# STM32G563 register map
File version: 2.0.0
CPU: CM33 r0p4, little endian, MPU, FPU, 4 interrupt priority bits
Registers are 32-bit, read-write, reset 0x0 unless marked. A register's access mark holds for its fields unless they carry their own. Offsets are from the block's base; [hi:lo] are bit positions; {n}, {i} and the like mark numbered series.

## CCB — CCB register block
Base 0x4600DC00
Same registers: CCB_S 0x5600DC00
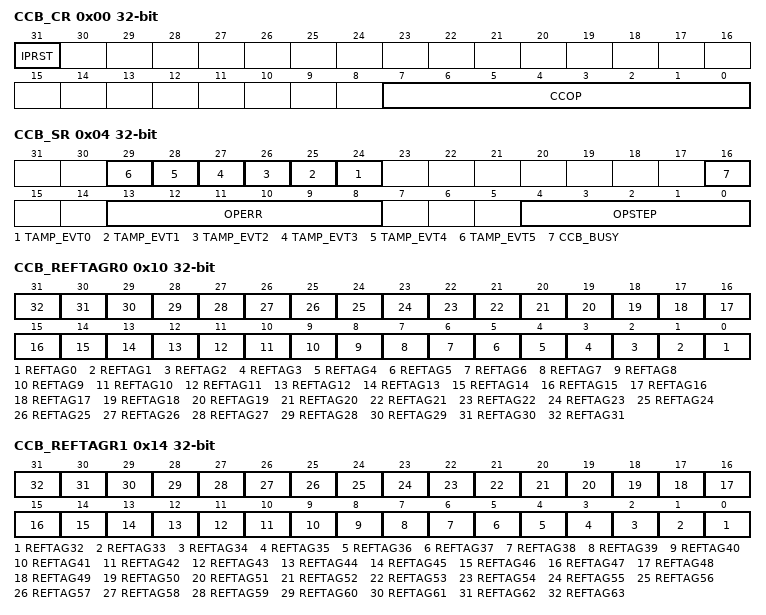
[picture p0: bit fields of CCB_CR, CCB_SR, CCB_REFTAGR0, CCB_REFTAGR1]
0x00 CCB_CR — CCB control register
  [31] IPRST — CCB reset
  [7:0] CCOP — Coupling and chaining operation
    68=Modular exponentiation blob creation with priv key from the CPU; 69=Modular exponentiation blob use; 128=ECC scalar multiplication blob creation with priv key from the CPU; 130=ECC scalar multiplication blob creation with priv key from the RNG; 129=ECC scalar multiplication blob use, or ECDSA signature blob use for public key computation; 192=ECDSA signature blob creation with priv key from the CPU; 194=ECDSA signature blob creation with priv key from the RNG; 195=ECDSA signature blob use for ECDSA signature
0x04 CCB_SR ro — CCB status register
  [n+24] TAMP_EVT{n} (n=0..5) — Tamper i flag
    0=No event; 1=Tamper event i has been raised. Global tamper event is raised. See Section43.3for details on the events.
  [16] CCB_BUSY
    0=CCB idle; 1=CCB busy or PKA RAM is being cleared following a peripheral reset
  [13:8] OPERR — Operation error
    0=No error detected during protected PKA operation (if applicable); 1=CCB RCC reset has been detected when OPSTEP > 0x0; 2=SAES RCC reset has been detected when OPSTEP > 0x0; 3=PKA RCC reset has been detected when OPSTEP > 0x0; 4=RNG RCC reset has been detected when OPSTEP > 0x0; 5=The RCC has gated the CCB clock when OPSTEP > 0x0; 6=The RCC has gated the SAES clock when OPSTEP > 0x0; 7=The RCC has gated the PKA clock when OPSTEP > 0x0; 8=The RCC has gated the RNG clock when OPSTEP > 0x0; 9=Random in SAES_IV1 is trivial (all 0s or all 1s) when OPSTEP = 0x2; 10=Random in SAES_IV2 is trivial (all 0s or all 1s) when OPSTEP = 0x2; 11=Random in SAES_IV3 is trivial (all 0s or all 1s) when OPSTEP = 0x2; 12=When OPSTEP = 0x17 SAES GCM TAG comparison with CCB_REFTAG failed, or a register different from SAES_DOUT was read in the SAES; 13=KEYSIZE different to 256 bits in SAES_CR when the SAES is enabled, and OPSTEP > 0x0; 14=CHMOD different to GCM in SAES_CR when 0x1 less than OPSTEP less than 0x18, or the SAES is not enabled, or KEYVALID is cleared when GCMPH > 0x0; 15=KMOD different from wrapped key mode in SAES_CR when the SAES is enabled, and; 16=KEYSEL different to 0x1 or 0x4 in SAES_CR when the SAES is enabled, KEYVALID is set, and OPSTEP=0x1; 17=GCMPH not correct (not incremented) in SAES_CR when OPSTEP > 0x1; 18=MODE in SAES_CR does not match the expected value (selected by CCOP in CCB_CR) when OPSTEP > 0x1; 19=BUSY = 1 in SAES_SR when OPSTEP= 0x18 or 0x19. SAES must not be used when PKA is computing a protected operation.; 20=EN = 0 in PKA_CR when OPSTEP > 0x2 (except 0x12). In other words, PKA must be enabled in any OPSTEP except 0x1, 0x2, or 0x12.; 21=INITOK = 0 in PKA_SR when OPSTEP > 0x2 (except 0x12); 22=Authorized by local firewall, but unexpected AHB error detected when OPSTEP > 0x0. 0x17: LMF = 1 in PKA_SR (only ECDSA verification available) when OPSTEP > 0x0.; 24=CCB_REFTAGRx registers are equal to 0 when OPSTEP > 0x12; 26=Security or/and privilege protection inconsistent (see Section5: Global TrustZoneless thansup> less than/sup> controller (GTZC)) for the peripherals SAES, PKA, RNG, and CCB when OPSTEP > 0x0. This error is also triggered when the protections change while OPSTEP > 0x0; 27=MODE in PKA_CR does not match the expected value (selected by CCOP in CCB_CR) when OPSTEP > 0x0; 28=OPSTEP end-step event not found at OPSTEP= 0x0 (SAES KEYVALID is set). Use CCB IPRST before starting a coupling and chaining operation.; 29=OPSTEP end-step event not found at OPSTEP = 0x1; 30=OPSTEP end-step event not found at OPSTEP = 0x2; 31=OPSTEP end-step event not found at OPSTEP = 0x3; 32=OPSTEP end-step event not found at OPSTEP = 0xA; 33=OPSTEP end-step event not found at OPSTEP = 0x12; 34=OPSTEP end-step event not found at OPSTEP = 0x13; 35=OPSTEP end-step event not found at OPSTEP = 0x17
  [4:0] OPSTEP — Operation step
0x10 CCB_REFTAGR0 — CCB reference tag register
  [n] REFTAG{n} (n=0..31) — Reference tag bits {n}
0x14 CCB_REFTAGR1 — CCB reference tag register
  [n-32] REFTAG{n} (n=32..63) — Reference tag bits {n}
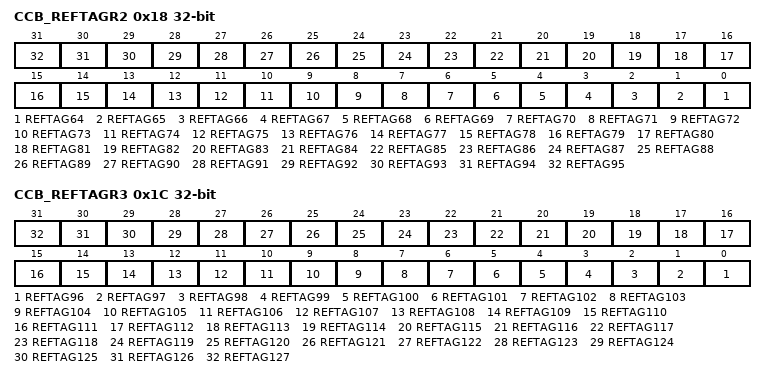
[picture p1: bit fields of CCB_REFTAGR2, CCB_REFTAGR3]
0x18 CCB_REFTAGR2 — CCB reference tag register
  [n-64] REFTAG{n} (n=64..95) — Reference tag bits {n}
0x1C CCB_REFTAGR3 — CCB reference tag register
  [n-96] REFTAG{n} (n=96..127) — Reference tag bits {n}
